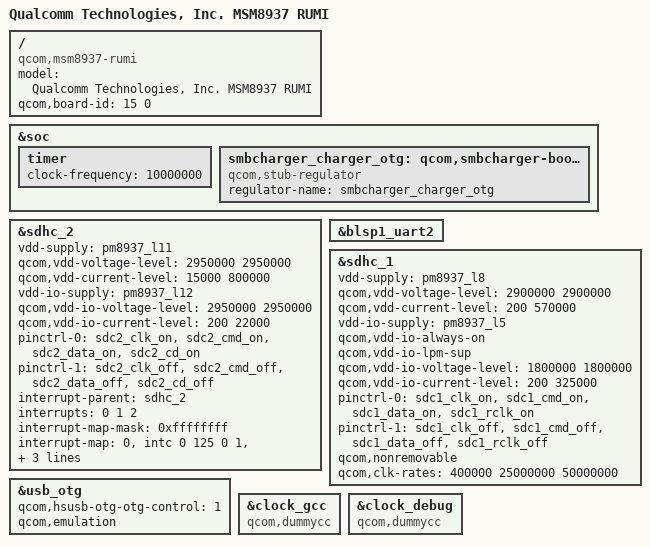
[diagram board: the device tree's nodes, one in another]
/*
 * Copyright (c) 2015, The Linux Foundation. All rights reserved.
 *
 * This program is free software; you can redistribute it and/or modify
 * it under the terms of the GNU General Public License version 2 and
 * only version 2 as published by the Free Software Foundation.
 *
 * This program is distributed in the hope that it will be useful,
 * but WITHOUT ANY WARRANTY; without even the implied warranty of
 * MERCHANTABILITY or FITNESS FOR A PARTICULAR PURPOSE.  See the
 * GNU General Public License for more details.
 */

/dts-v1/;

#include "msm8937.dtsi"

/ {
	model = "Qualcomm Technologies, Inc. MSM8937 RUMI";
	compatible = "qcom,msm8937-rumi", "qcom,msm8937", "qcom,rumi";
	qcom,board-id= <15 0>;
};


&soc {
	timer {
		clock-frequency = <10000000>;
	};

	smbcharger_charger_otg: qcom,smbcharger-boost-otg {
		compatible = "qcom,stub-regulator";
		regulator-name = "smbcharger_charger_otg";
	};
};

&sdhc_2 {
	/* device core power supply */
	vdd-supply = <&pm8937_l11>;
	qcom,vdd-voltage-level = <2950000 2950000>;
	qcom,vdd-current-level = <15000 800000>;

	/* device communication power supply */
	vdd-io-supply = <&pm8937_l12>;
	qcom,vdd-io-voltage-level = <2950000 2950000>;
	qcom,vdd-io-current-level = <200 22000>;

	pinctrl-names = "active", "sleep";
	pinctrl-0 = <&sdc2_clk_on &sdc2_cmd_on &sdc2_data_on &sdc2_cd_on>;
	pinctrl-1 = <&sdc2_clk_off &sdc2_cmd_off &sdc2_data_off &sdc2_cd_off>;

	#address-cells = <0>;
	interrupt-parent = <&sdhc_2>;
	interrupts = <0 1 2>;
	#interrupt-cells = <1>;
	interrupt-map-mask = <0xffffffff>;
	interrupt-map = <0 &intc 0 125 0
			1 &intc 0 221 0
			2 &tlmm 67 0>;
	interrupt-names = "hc_irq", "pwr_irq", "status_irq";
	cd-gpios = <&tlmm 67 0x1>;

	qcom,clk-rates = <400000 25000000 50000000>;

	status = "ok";
};

&blsp1_uart2 {
	status = "ok";
};

&sdhc_1 {
	/* device core power supply */
	vdd-supply = <&pm8937_l8>;
	qcom,vdd-voltage-level = <2900000 2900000>;
	qcom,vdd-current-level = <200 570000>;

	/* device communication power supply */
	vdd-io-supply = <&pm8937_l5>;
	qcom,vdd-io-always-on;
	qcom,vdd-io-lpm-sup;
	qcom,vdd-io-voltage-level = <1800000 1800000>;
	qcom,vdd-io-current-level = <200 325000>;

	pinctrl-names = "active", "sleep";
	pinctrl-0 = <&sdc1_clk_on &sdc1_cmd_on &sdc1_data_on &sdc1_rclk_on>;
	pinctrl-1 = <&sdc1_clk_off &sdc1_cmd_off &sdc1_data_off &sdc1_rclk_off>;

	qcom,nonremovable;
	qcom,clk-rates = <400000 25000000 50000000>;

	status = "ok";
};

&usb_otg {
	qcom,hsusb-otg-otg-control = <1>;
	qcom,emulation;
	/delete-property/ qcom,boost-sysclk-with-streaming;
};

&clock_gcc {
	compatible = "qcom,dummycc";
};

&clock_debug {
	compatible = "qcom,dummycc";
};
